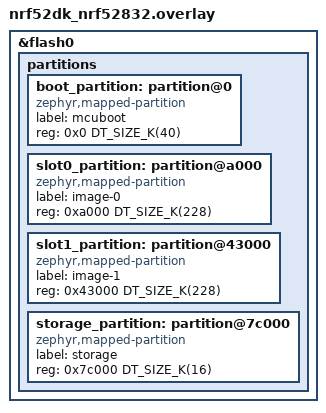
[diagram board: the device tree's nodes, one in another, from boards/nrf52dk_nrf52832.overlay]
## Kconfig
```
#
# Copyright (c) 2018 Nordic Semiconductor
#
# SPDX-License-Identifier: LicenseRef-Nordic-5-Clause
#

# Make the NCS SMP-BLE OTA DFU sample option (CONFIG_NCS_SAMPLE_MCUMGR_BT_OTA_DFU)
# available to this application.
osource "$(ZEPHYR_NRF_MODULE_DIR)/samples/common/mcumgr_bt_ota_dfu/Kconfig"

source "Kconfig.zephyr"

menu "Nordic LED-Button BLE GATT service sample"

config BT_LBS_SECURITY_ENABLED
	bool "Enable security"
	default y
	select BT_SMP
	select BT_SETTINGS
	select FLASH
	select FLASH_PAGE_LAYOUT
	select FLASH_MAP
	select ZMS if (SOC_FLASH_NRF_RRAM || SOC_FLASH_NRF_MRAM)
	select NVS if !(SOC_FLASH_NRF_RRAM || SOC_FLASH_NRF_MRAM)
	select SETTINGS
	help
	  "Enable BLE security for the LED-Button service"

endmenu
```

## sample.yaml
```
sample:
  description: nRF Connect SDK Intermediate Course by Nordic Developer Academy (https://academy.nordicsemi.com/)
  name: nRF Connect SDK Intermediate Course - Lesson 9 Exercise 6 Solution (FOTA over BLE via nRF Cloud)
  
common: 
    sysbuild: true
    build_only: true
    integration_platforms: 
      - nrf52dk/nrf52832
      - nrf52833dk/nrf52833
      - nrf52840dk/nrf52840
      - nrf5340dk/nrf5340/cpuapp
      - nrf5340dk/nrf5340/cpuapp/ns
      - nrf54l15dk/nrf54l15/cpuapp
      - nrf54lc10dk/nrf54lc10a/cpuapp
      - nrf54ls05dk/nrf54ls05b/cpuapp
      - nrf54lm20dk/nrf54lm20a/cpuapp
    platform_allow:
      - nrf52dk/nrf52832
      - nrf52833dk/nrf52833
      - nrf52840dk/nrf52840
      - nrf5340dk/nrf5340/cpuapp
      - nrf5340dk/nrf5340/cpuapp/ns
      - nrf54l15dk/nrf54l15/cpuapp
      - nrf54lc10dk/nrf54lc10a/cpuapp
      - nrf54ls05dk/nrf54ls05b/cpuapp
      - nrf54lm20dk/nrf54lm20a/cpuapp
    
tests:
  ncs_inter.l9.e6_sol: {}
```

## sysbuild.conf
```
SB_CONFIG_BOOTLOADER_MCUBOOT=y
```

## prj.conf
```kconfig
#
# Copyright (c) 2018 Nordic Semiconductor
#
# SPDX-License-Identifier: LicenseRef-Nordic-5-Clause
#
CONFIG_NCS_SAMPLES_DEFAULTS=y

CONFIG_BT=y
CONFIG_BT_PERIPHERAL=y
CONFIG_BT_DEVICE_NAME="Nordic_LBS"

# Enable the LBS service
CONFIG_BT_LBS=y
CONFIG_BT_LBS_POLL_BUTTON=y
CONFIG_DK_LIBRARY=y

CONFIG_SYSTEM_WORKQUEUE_STACK_SIZE=2048

# Carried over from Exercise 5: FOTA over Bluetooth LE (MCUboot is enabled in sysbuild.conf)
CONFIG_NCS_SAMPLE_MCUMGR_BT_OTA_DFU=y
# Show OS/firmware version fields in the nRF Connect Device Manager app
CONFIG_MCUMGR_GRP_OS_INFO=y

# STEP 1.1 - Preserve Bluetooth bonds across a firmware upgrade.
# Because the device stores settings in ZMS/NVS, the OTA DFU sample auto-enables a basic-group
# "storage erase" command that lets the Device Manager app wipe the settings partition (and your
# bonds) during an update. Disable it so the bond survives the upgrade and the phone reconnects
# without re-pairing.
CONFIG_MCUMGR_GRP_ZBASIC_STORAGE_ERASE=n

# STEP 1.2 - Enable the Memfault SDK and set your nRF Cloud (powered by Memfault) project key
CONFIG_MEMFAULT=y
CONFIG_MEMFAULT_NCS_PROJECT_KEY="your-project-key-here"
CONFIG_MEMFAULT_LOG_LEVEL_INF=y
# Software type reported to nRF Cloud. Must match the OTA release's Software Type. nRF Cloud ties
# the nrf54l15dk hardware type to "main", so report "main" (NCS otherwise defaults this to "app").
CONFIG_MEMFAULT_NCS_FW_TYPE="main"

# STEP 1.3 - Enable the Memfault Diagnostic Service (MDS) so the device's data
# (current firmware version, heartbeats, crashes) reaches nRF Cloud over BLE.
# MDS access is gated behind an encrypted connection, so privacy/bonding is required.
CONFIG_BT_MDS=y
CONFIG_BT_PRIVACY=y

# STEP 1.4 - Provide the Memfault device serial automatically from the hardware UID
CONFIG_HW_ID_LIBRARY=y
CONFIG_HW_ID_LIBRARY_SOURCE_DEVICE_ID=y

# STEP 1.5 - Set the firmware version. The two strings must always match.
# The solution shows the second release (0.0.2) delivered over the air; the
# first image flashed to the device in the exercise is 0.0.1.
CONFIG_MEMFAULT_NCS_FW_VERSION_STATIC=y
CONFIG_MEMFAULT_NCS_FW_VERSION="0.0.2"
CONFIG_MCUBOOT_IMGTOOL_SIGN_VERSION="0.0.2"
```

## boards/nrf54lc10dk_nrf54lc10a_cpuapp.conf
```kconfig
CONFIG_CBPRINTF_NANO=y
CONFIG_LOG_MODE_MINIMAL=y
CONFIG_ASSERT=n
CONFIG_BOOT_BANNER=n
```

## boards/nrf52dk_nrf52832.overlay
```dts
/*
 * nRF52833DK flash re-partition (Partition Manager disabled, DTS authoritative).
 *
 * Change vs. the board default: mcuboot (boot_partition) is 8 KB smaller and the
 * application slot (slot0_partition / image-0) is 8 KB bigger. slot0's end address
 * is unchanged, so slot1 and storage keep their original addresses.
 *
 * MCUboot swap-based DFU requires slot0 and slot1 to be equal, so slot1 also grows
 * to 228 KB; the extra 8 KB is reclaimed from storage (24 KB -> 16 KB).
 *
 *   boot_partition    0x00000  40 KB  (was 48 KB)
 *   slot0_partition   0x0a000 228 KB  (was 220 KB)
 *   slot1_partition   0x43000 228 KB  (was 220 KB)
 *   storage_partition 0x7c000  16 KB  (was 24 KB)
 */

/delete-node/ &boot_partition;
/delete-node/ &slot0_partition;
/delete-node/ &slot1_partition;
/delete-node/ &storage_partition;

&flash0 {
	partitions {
		boot_partition: partition@0 {
			compatible = "zephyr,mapped-partition";
			label = "mcuboot";
			reg = <0x0 DT_SIZE_K(40)>;
		};

		slot0_partition: partition@a000 {
			compatible = "zephyr,mapped-partition";
			label = "image-0";
			reg = <0xa000 DT_SIZE_K(228)>;
		};

		slot1_partition: partition@43000 {
			compatible = "zephyr,mapped-partition";
			label = "image-1";
			reg = <0x43000 DT_SIZE_K(228)>;
		};

		storage_partition: partition@7c000 {
			compatible = "zephyr,mapped-partition";
			label = "storage";
			reg = <0x7c000 DT_SIZE_K(16)>;
		};
	};
};
```

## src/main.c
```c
/*
 * Copyright (c) 2018 Nordic Semiconductor ASA
 *
 * SPDX-License-Identifier: LicenseRef-Nordic-5-Clause
 */

#include <zephyr/types.h>
#include <stddef.h>
#include <string.h>
#include <errno.h>
#include <zephyr/sys/printk.h>
#include <zephyr/sys/byteorder.h>
#include <zephyr/kernel.h>
#include <zephyr/drivers/gpio.h>
#include <soc.h>

#include <zephyr/bluetooth/bluetooth.h>
#include <zephyr/bluetooth/hci.h>
#include <zephyr/bluetooth/conn.h>
#include <zephyr/bluetooth/uuid.h>
#include <zephyr/bluetooth/gatt.h>

#include <bluetooth/services/lbs.h>

/* STEP 2.1 - Include the Memfault Diagnostic Service header */
#include <bluetooth/services/mds.h>

#include <zephyr/settings/settings.h>

#include <dk_buttons_and_leds.h>

#define DEVICE_NAME             CONFIG_BT_DEVICE_NAME
#define DEVICE_NAME_LEN         (sizeof(DEVICE_NAME) - 1)


#define RUN_STATUS_LED          DK_LED1
#define CON_STATUS_LED          DK_LED2
#define RUN_LED_BLINK_INTERVAL  1000

#define USER_LED                DK_LED3

#define USER_BUTTON             DK_BTN1_MSK

static bool app_button_state;
static struct k_work adv_work;

#if defined(CONFIG_BT_MDS)
/* STEP 2.2 - Track the connection that is allowed to access MDS */
static struct bt_conn *mds_conn;
#endif

static const struct bt_data ad[] = {
	BT_DATA_BYTES(BT_DATA_FLAGS, (BT_LE_AD_GENERAL | BT_LE_AD_NO_BREDR)),
	BT_DATA(BT_DATA_NAME_COMPLETE, DEVICE_NAME, DEVICE_NAME_LEN),
};

static const struct bt_data sd[] = {
	BT_DATA_BYTES(BT_DATA_UUID128_ALL, BT_UUID_LBS_VAL),
};

static void adv_work_handler(struct k_work *work)
{
	int err = bt_le_adv_start(BT_LE_ADV_CONN_FAST_2, ad, ARRAY_SIZE(ad), sd, ARRAY_SIZE(sd));

	if (err) {
		printk("Advertising failed to start (err %d)\n", err);
		return;
	}

	printk("Advertising successfully started\n");
}

static void advertising_start(void)
{
	k_work_submit(&adv_work);
}

static void connected(struct bt_conn *conn, uint8_t err)
{
	if (err) {
		printk("Connection failed, err 0x%02x %s\n", err, bt_hci_err_to_str(err));
		return;
	}

	printk("Connected\n");

	dk_set_led_on(CON_STATUS_LED);

#if defined(CONFIG_BT_MDS)
	/* STEP 2.3 - Request an encrypted link. MDS data may only be accessed
	 * over an encrypted (and, here, bonded) connection.
	 */
	bt_conn_set_security(conn, BT_SECURITY_L2);
#endif
}

static void disconnected(struct bt_conn *conn, uint8_t reason)
{
	printk("Disconnected, reason 0x%02x %s\n", reason, bt_hci_err_to_str(reason));

	dk_set_led_off(CON_STATUS_LED);
/* STEP 2.3 (cont.) - Clear mds_conn here if it matches the closing connection */
#if defined(CONFIG_BT_MDS)
	if (conn == mds_conn) {
		mds_conn = NULL;
	}
#endif
}

static void recycled_cb(void)
{
	printk("Connection object available from previous conn. Disconnect is complete!\n");
	advertising_start();
}

#ifdef CONFIG_BT_LBS_SECURITY_ENABLED
static void security_changed(struct bt_conn *conn, bt_security_t level,
			     enum bt_security_err err)
{
	char addr[BT_ADDR_LE_STR_LEN];

	bt_addr_le_to_str(bt_conn_get_dst(conn), addr, sizeof(addr));

	if (!err) {
		printk("Security changed: %s level %u\n", addr, level);
	} else {
		printk("Security failed: %s level %u err %d %s\n", addr, level, err,
		       bt_security_err_to_str(err));
	}

#if defined(CONFIG_BT_MDS)
	/* STEP 2.4 - Once the link is encrypted, allow this connection to access MDS */
	if (!err && level >= BT_SECURITY_L2 && !mds_conn) {
		mds_conn = conn;
	}
#endif
}
#endif

BT_CONN_CB_DEFINE(conn_callbacks) = {
	.connected        = connected,
	.disconnected     = disconnected,
	.recycled         = recycled_cb,
#ifdef CONFIG_BT_LBS_SECURITY_ENABLED
	.security_changed = security_changed,
#endif
};

#if defined(CONFIG_BT_LBS_SECURITY_ENABLED)
/* No passkey display/entry callbacks -> pairing uses "Just Works" (no PIN),
 * which still yields an encrypted link (BT_SECURITY_L2) for MDS access.
 */
static void auth_cancel(struct bt_conn *conn)
{
	char addr[BT_ADDR_LE_STR_LEN];

	bt_addr_le_to_str(bt_conn_get_dst(conn), addr, sizeof(addr));

	printk("Pairing cancelled: %s\n", addr);
}

static void pairing_complete(struct bt_conn *conn, bool bonded)
{
	char addr[BT_ADDR_LE_STR_LEN];

	bt_addr_le_to_str(bt_conn_get_dst(conn), addr, sizeof(addr));

	printk("Pairing completed: %s, bonded: %d\n", addr, bonded);
}

static void pairing_failed(struct bt_conn *conn, enum bt_security_err reason)
{
	char addr[BT_ADDR_LE_STR_LEN];

	bt_addr_le_to_str(bt_conn_get_dst(conn), addr, sizeof(addr));

	printk("Pairing failed conn: %s, reason %d %s\n", addr, reason,
	       bt_security_err_to_str(reason));
}

static struct bt_conn_auth_cb conn_auth_callbacks = {
	.cancel = auth_cancel,
};

static struct bt_conn_auth_info_cb conn_auth_info_callbacks = {
	.pairing_complete = pairing_complete,
	.pairing_failed = pairing_failed
};
#else
static struct bt_conn_auth_cb conn_auth_callbacks;
static struct bt_conn_auth_info_cb conn_auth_info_callbacks;
#endif

#if defined(CONFIG_BT_MDS)
/* STEP 2.5 - Only allow the paired/encrypted connection to access MDS */
static bool mds_access_enable(struct bt_conn *conn)
{
	if (mds_conn && (conn == mds_conn)) {
		return true;
	}

	return false;
}

static const struct bt_mds_cb mds_cb = {
	.access_enable = mds_access_enable,
};
#endif /* CONFIG_BT_MDS */

static void app_led_cb(bool led_state)
{
	dk_set_led(USER_LED, led_state);
}

static bool app_button_cb(void)
{
	return app_button_state;
}

static struct bt_lbs_cb lbs_callbacs = {
	.led_cb    = app_led_cb,
	.button_cb = app_button_cb,
};

static void button_changed(uint32_t button_state, uint32_t has_changed)
{
	if (has_changed & USER_BUTTON) {
		uint32_t user_button_state = button_state & USER_BUTTON;

		bt_lbs_send_button_state(user_button_state);
		app_button_state = user_button_state ? true : false;
	}
}

static int init_button(void)
{
	int err;

	err = dk_buttons_init(button_changed);
	if (err) {
		printk("Cannot init buttons (err: %d)\n", err);
	}

	return err;
}

int main(void)
{
	int blink_status = 0;
	int err;

	printk("Starting Bluetooth Peripheral LBS sample\n");

	err = dk_leds_init();
	if (err) {
		printk("LEDs init failed (err %d)\n", err);
		return 0;
	}

	err = init_button();
	if (err) {
		printk("Button init failed (err %d)\n", err);
		return 0;
	}

#if defined(CONFIG_BT_MDS)
	/* STEP 2.6 - Register the MDS access callback before enabling Bluetooth */
	err = bt_mds_cb_register(&mds_cb);
	if (err) {
		printk("Memfault Diagnostic service callback registration failed (err %d)\n", err);
		return 0;
	}
#endif

	if (IS_ENABLED(CONFIG_BT_LBS_SECURITY_ENABLED)) {
		err = bt_conn_auth_cb_register(&conn_auth_callbacks);
		if (err) {
			printk("Failed to register authorization callbacks.\n");
			return 0;
		}

		err = bt_conn_auth_info_cb_register(&conn_auth_info_callbacks);
		if (err) {
			printk("Failed to register authorization info callbacks.\n");
			return 0;
		}
	}

	err = bt_enable(NULL);
	if (err) {
		printk("Bluetooth init failed (err %d)\n", err);
		return 0;
	}

	printk("Bluetooth initialized\n");

	if (IS_ENABLED(CONFIG_SETTINGS)) {
		settings_load();
	}

	err = bt_lbs_init(&lbs_callbacs);
	if (err) {
		printk("Failed to init LBS (err:%d)\n", err);
		return 0;
	}

	k_work_init(&adv_work, adv_work_handler);
	advertising_start();

	for (;;) {
		dk_set_led(RUN_STATUS_LED, (++blink_status) % 2);
		k_sleep(K_MSEC(RUN_LED_BLINK_INTERVAL));
	}
}
```

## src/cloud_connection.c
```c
/* Copyright (c) 2023 Nordic Semiconductor ASA
 *
 * SPDX-License-Identifier: LicenseRef-Nordic-5-Clause
 */

#include <zephyr/kernel.h>
#include <zephyr/net/socket.h>
#include <zephyr/net/conn_mgr_connectivity.h>
#include <zephyr/logging/log.h>
#include <stdio.h>
#include <date_time.h>
#include <net/nrf_cloud.h>
#include <net/nrf_cloud_codec.h>
#include <net/nrf_cloud_log.h>
#include "app_version.h"

/* STEP 6.1.1 - Dependency for sys_reboot() */
#include <zephyr/sys/reboot.h>

#include "cloud_connection.h"

LOG_MODULE_REGISTER(cloud_connection, 4);

/* Internal state */

/* Pendable events that threads can wait for. */
#define NETWORK_READY			BIT(0)
#define CLOUD_CONNECTED			BIT(1)
#define CLOUD_READY			BIT(2)
#define CLOUD_DISCONNECTED		BIT(3)
#define DATE_TIME_KNOWN			BIT(4)
static K_EVENT_DEFINE(cloud_events);

/* Atomic status flag tracking whether an initial association is in progress. */
atomic_t initial_association;

/* Helper functions for pending on pendable events. */
bool await_network_ready(k_timeout_t timeout)
{
	return k_event_wait(&cloud_events, NETWORK_READY, false, timeout) != 0;
}

bool await_cloud_ready(k_timeout_t timeout)
{
	return k_event_wait(&cloud_events, CLOUD_READY, false, timeout) != 0;
}

bool await_cloud_disconnected(k_timeout_t timeout)
{
	return k_event_wait(&cloud_events, CLOUD_DISCONNECTED, false, timeout) != 0;
}

bool await_date_time_known(k_timeout_t timeout)
{
	return k_event_wait(&cloud_events, DATE_TIME_KNOWN, false, timeout) != 0;
}

/* Wait for a connection result, and return true if connection was successful within the timeout,
 * otherwise return false.
 */
static bool await_connection_result(k_timeout_t timeout)
{
	/* After a connection attempt, either CLOUD_CONNECTED or CLOUD_DISCONNECTED will be
	 * raised, depending on whether the connection succeeded.
	 */
	uint32_t events = CLOUD_CONNECTED | CLOUD_DISCONNECTED;

	return (k_event_wait(&cloud_events, events, false, timeout) & CLOUD_CONNECTED) != 0;
}

/* Delayable work item for handling cloud readiness timeout.
 * The work item is scheduled at a delay any time connection starts and is cancelled when the
 * connection to nRF Cloud becomes ready to use (signalled by NRF_CLOUD_EVT_READY).
 *
 * If the work item executes, that means the nRF Cloud connection did not become ready for use
 * within the delay, and thus the connection should be reset (and then try again later).
 */
static void ready_timeout_work_fn(struct k_work *work)
{
	ARG_UNUSED(work);
	LOG_INF("nRF Cloud connection did not become ready in time, disconnecting and retrying...");
	disconnect_cloud();
}

static K_WORK_DELAYABLE_DEFINE(ready_timeout_work, ready_timeout_work_fn);


/* Start the readiness timeout if readiness is not already achieved. */
static void start_readiness_timeout(void)
{
	/* It doesn't make sense to start the readiness timeout if we're already ready. */
	if (!k_event_test(&cloud_events, CLOUD_READY)) {
		return;
	}

	LOG_DBG("Starting cloud connection readiness timeout for %d seconds",600);
	k_work_reschedule(&ready_timeout_work, K_SECONDS(600));
}

static void clear_readiness_timeout(void)
{
	LOG_DBG("Stopping cloud connection readiness timeout");
	k_work_cancel_delayable(&ready_timeout_work);
}

/**
 * @brief Update internal state in response to achieving connection.
 */
static void cloud_connected(void)
{
	LOG_INF("Connected to nRF Cloud");

	/* Notify that the nRF Cloud connection is established. */
	k_event_post(&cloud_events, CLOUD_CONNECTED);
}

/**
 * @brief Update internal state in response to achieving readiness.
 */
static void cloud_ready(void)
{
	/* Clear the readiness timeout, since we have become ready. */
	clear_readiness_timeout();

	/* Notify that the nRF Cloud connection is ready for use. */
	k_event_post(&cloud_events, CLOUD_READY);
}

/* A callback that the application may register in order to handle custom device messages.
 * This is really a convenience callback to help keep this sample clean and modular. You could
 * implement device message handling directly in the cloud_event_handler if desired.
 */
static dev_msg_handler_cb_t general_dev_msg_handler;
void register_general_dev_msg_handler(dev_msg_handler_cb_t handler_cb)
{
	general_dev_msg_handler = handler_cb;
}

/* This function causes the cloud to disconnect, and updates internal state accordingly.
 *
 * It is also triggerd by cloud disconnection, to update internal state.
 *
 * In this latter case, an unnecessary "Disconnecting from nRF Cloud" and
 * "Already disconnected from nRF Cloud" will be printed.
 *
 * This is done to keep the sample simple, though the log messages may be a bit confusing.
 */
void disconnect_cloud(void)
{
	/* Clear the readiness timeout in case it was running. */
	clear_readiness_timeout();

	/* Clear the Ready and Connected events, no longer accurate. */
	k_event_clear(&cloud_events, CLOUD_READY | CLOUD_CONNECTED);

	/* Clear the initial association flag, no longer accurate. */
	atomic_set(&initial_association, false);

	/* Disconnect from nRF Cloud -- Blocking call
	 * Will no-op and return -EACCES if already disconnected.
	 */
	LOG_INF("Disconnecting from nRF Cloud");
	int err;

	err = nrf_cloud_disconnect();
	/* nrf_cloud_disconnect returns -EACCES if we are not currently in a connected state.
	 * nrf_cloud_coap_disconnect returns -ENOTCONN if socket is not open.
	 */
	if ((err == -EACCES) || (err == -ENOTCONN)) {
		LOG_DBG("Already disconnected from nRF Cloud");
	} else if (err) {
		LOG_ERR("Cannot disconnect from nRF Cloud, error: %d. Continuing anyways", err);
	} else {
		LOG_INF("Successfully disconnected from nRF Cloud");
	}

	/* Fire the disconnected event. */
	k_event_post(&cloud_events, CLOUD_DISCONNECTED);
}

/**
 * @brief Attempt to connect to nRF Cloud and update internal state accordingly.
 *
 * Blocks until connection attempt either succeeds or fails.
 *
 * @retval true if successful
 * @retval false if connection failed
 */
static bool connect_cloud(void)
{
	char device_id[NRF_CLOUD_CLIENT_ID_MAX_LEN + 1];
	int err;

	LOG_INF("Connecting to nRF Cloud");

	err = nrf_cloud_client_id_get(device_id, sizeof(device_id));
	if (!err) {
		LOG_INF("Device ID: %s", device_id);
	} else {
		LOG_ERR("Error requesting the device id: %d", err);
	}

	/* Clear the disconnected flag, no longer accurate. */
	k_event_clear(&cloud_events, CLOUD_DISCONNECTED);

	/* Connect to nRF Cloud -- Non-blocking. State updates are handled in callbacks. */
	err = nrf_cloud_connect();

	/* If we were already connected, treat as a successful connection, but do nothing. */
	if (err == NRF_CLOUD_CONNECT_RES_ERR_ALREADY_CONNECTED) {
		LOG_WRN("Already connected to nRF Cloud");
		return true;
	}

	/* If the connection attempt fails immediately, report and exit. */
	if (err != 0) {
		LOG_ERR("Could not connect to nRF Cloud, error: %d", err);
		return false;
	}

	/* Wait for the connection to either complete or fail. */
	if (!await_connection_result(K_FOREVER)) {
		LOG_ERR("Could not connect to nRF Cloud");
		return false;
	}

	/* If connection succeeded and we aren't already ready, start the readiness timeout.
	 * (Readiness check is performed by start_readiness_timeout).
	 */
	start_readiness_timeout();
	return true;
}

/* External event handlers */

/* Handler for L4/connectivity events
 * This allows the cloud module to react to network gain and loss.
 * The conn_mgr subsystem is responsible for seeking / maintaining network connectivity and
 * firing these events.
 */
static struct net_mgmt_event_callback l4_callback;
static void l4_event_handler(struct net_mgmt_event_callback *cb,
			     uint64_t event, struct net_if *iface)
{
	if (event == NET_EVENT_L4_CONNECTED) {
		LOG_INF("Network connectivity gained!");

		k_sleep(K_MSEC(1000));

		/* Set the network ready flag */
		k_event_post(&cloud_events, NETWORK_READY);

		/* If LTE-event-driven date_time updates are disabled, manually trigger a date_time
		 * timestamp refresh.
		 *
		 * Note: The CONFIG_DATE_TIME_AUTO_UPDATE setting controls specifically whether
		 * LTE-event-driven date_time updates are enabled. The date_time library will still
		 * periodically refresh its timestamp if CONFIG_DATE_TIME_AUTO_UPDATE is disabled,
		 * but this refresh is infrequent, so we are manually requesting a refresh
		 * whenever internet access becomes available so that we get a timestamp
		 * immediately.
		 */

	} else if (event == NET_EVENT_L4_DISCONNECTED) {
		LOG_INF("Network connectivity lost!");

		/* Clear the network ready flag */
		k_event_clear(&cloud_events, NETWORK_READY);

		/* Disconnect from cloud as well. */
		disconnect_cloud();
	}
}

/* Handler for date_time library events, used to keep track of whether the current time is known */
static void date_time_event_handler(const struct date_time_evt *date_time_evt)
{
	if (date_time_is_valid()) {
		k_event_post(&cloud_events, DATE_TIME_KNOWN);
	} else {
		k_event_clear(&cloud_events, DATE_TIME_KNOWN);
	}
}

#if defined(CONFIG_NRF_CLOUD_MQTT)
/* Handler for nRF Cloud shadow events */
static void handle_shadow_event(struct nrf_cloud_obj_shadow_data *const shadow)
{
	if (!shadow) {
		return;
	}

	int err;

	if (shadow->type == NRF_CLOUD_OBJ_SHADOW_TYPE_DELTA) {
		LOG_DBG("Shadow: Delta - version: %d, timestamp: %lld",
			shadow->delta->ver,
			shadow->delta->ts);

		/* Always accept since this sample, by default,
		 * doesn't have any application specific shadow handling
		 */
		err = nrf_cloud_obj_shadow_delta_response_encode(&shadow->delta->state, true);
		if (err) {
			LOG_ERR("Failed to encode shadow response: %d", err);
			return;
		}

		err = nrf_cloud_obj_shadow_update(&shadow->delta->state);
		if (err) {
			LOG_ERR("Failed to send shadow response, error: %d", err);
		}
	} else if ((shadow->type == NRF_CLOUD_OBJ_SHADOW_TYPE_TF) && shadow->transform)
	{
		if (shadow->transform->is_err) {
			LOG_ERR("Shadow transform error received");
			return;
		}
		LOG_DBG("Shadow transform result received");
	}
}

/* Handler for events from nRF Cloud Lib. */
static void cloud_event_handler(const struct nrf_cloud_evt *nrf_cloud_evt)
{
	switch (nrf_cloud_evt->type) {
	case NRF_CLOUD_EVT_TRANSPORT_CONNECTED:
		LOG_DBG("NRF_CLOUD_EVT_TRANSPORT_CONNECTED");

		/* Handle connection success. */
		cloud_connected();
		break;
	case NRF_CLOUD_EVT_TRANSPORT_CONNECTING:
		LOG_DBG("NRF_CLOUD_EVT_TRANSPORT_CONNECTING");
		break;
	case NRF_CLOUD_EVT_TRANSPORT_CONNECT_ERROR:
		LOG_DBG("NRF_CLOUD_EVT_TRANSPORT_CONNECT_ERROR: %d", nrf_cloud_evt->status);

		/* Disconnect from cloud immediately rather than wait for retry timeout. */
		disconnect_cloud();

		break;
	case NRF_CLOUD_EVT_USER_ASSOCIATION_REQUEST:
		LOG_DBG("NRF_CLOUD_EVT_USER_ASSOCIATION_REQUEST");
		/* This event indicates that the user must associate the device with their
		 * nRF Cloud account in the nRF Cloud portal.
		 *
		 * The device must then disconnect and reconnect to nRF Cloud after association
		 * succeeds.
		 */
		LOG_INF("Please add this device to your cloud account in the nRF Cloud portal.");

		/* Store the fact that this is an initial association.
		 *
		 * This will cause the next NRF_CLOUD_EVT_USER_ASSOCIATED event to
		 * disconnect and reconnect the device to nRF Cloud, which is required
		 * when devices are first associated with an nRF Cloud account.
		 */
		atomic_set(&initial_association, true);
		break;
	case NRF_CLOUD_EVT_USER_ASSOCIATED:
		LOG_DBG("NRF_CLOUD_EVT_USER_ASSOCIATED");
		/* Indicates successful association with an nRF Cloud account.
		 * Fired every time the device connects (unless the device is not associated).
		 *
		 * If this is an initial association, the device must disconnect and
		 * and reconnect before using nRF Cloud.
		 */

		if (atomic_get(&initial_association)) {
			/* Disconnect as is required.
			 * The connection loop will handle reconnection afterwards.
			 */
			LOG_INF("Device successfully associated with cloud! Reconnecting");
			disconnect_cloud();
		}
		break;
	case NRF_CLOUD_EVT_READY:
		LOG_DBG("NRF_CLOUD_EVT_READY");

		/* Handle achievement of readiness */
		cloud_ready();

		/* The nRF Cloud library will automatically update the
		 * device's shadow based on the build configuration.
		 * See config NRF_CLOUD_SEND_SHADOW_INFO for details.
		 */

		break;
	case NRF_CLOUD_EVT_SENSOR_DATA_ACK:
		LOG_DBG("NRF_CLOUD_EVT_SENSOR_DATA_ACK");
		break;
	case NRF_CLOUD_EVT_TRANSPORT_DISCONNECTED:
		LOG_DBG("NRF_CLOUD_EVT_TRANSPORT_DISCONNECTED");

		/* The nRF Cloud library itself has disconnected for some reason.
		 * Execute a manual disconnect so that the event flags are updated.
		 * The internal nrf_cloud_disconnect call will no-op.
		 */
		disconnect_cloud();

		break;
	case NRF_CLOUD_EVT_ERROR:
		LOG_DBG("NRF_CLOUD_EVT_ERROR: %d", nrf_cloud_evt->status);
		break;
	case NRF_CLOUD_EVT_RX_DATA_GENERAL:
		LOG_DBG("NRF_CLOUD_EVT_RX_DATA_GENERAL");
		LOG_DBG("%d bytes received from cloud", nrf_cloud_evt->data.len);

		/* Pass the device message along to the application, if it is listening */
		if (general_dev_msg_handler) {
			/* To keep the sample simple, we invoke the callback directly.
			 * If you want to do complex operations in this callback without blocking
			 * receipt of data from nRF Cloud, you should set up a work queue and pass
			 * messages to it either here, or from inside the callback.
			 */
			general_dev_msg_handler(&nrf_cloud_evt->data);
		}

		break;
	case NRF_CLOUD_EVT_RX_DATA_SHADOW: {
		LOG_DBG("NRF_CLOUD_EVT_RX_DATA_SHADOW");
		handle_shadow_event(nrf_cloud_evt->shadow);
		break;
	}
	case NRF_CLOUD_EVT_FOTA_START:
		LOG_DBG("NRF_CLOUD_EVT_FOTA_START");
		break;
	case NRF_CLOUD_EVT_FOTA_DONE: {
		enum nrf_cloud_fota_type fota_type = NRF_CLOUD_FOTA_TYPE__INVALID;

		if (nrf_cloud_evt->data.ptr) {
			fota_type = *((enum nrf_cloud_fota_type *) nrf_cloud_evt->data.ptr);
		}

		LOG_DBG("NRF_CLOUD_EVT_FOTA_DONE, FOTA type: %s",
			fota_type == NRF_CLOUD_FOTA_APPLICATION	  ?		"Application"	:
			fota_type == NRF_CLOUD_FOTA_MODEM_DELTA	  ?		"Modem (delta)"	:
			fota_type == NRF_CLOUD_FOTA_MODEM_FULL	  ?		"Modem (full)"	:
			fota_type == NRF_CLOUD_FOTA_BOOTLOADER	  ?		"Bootloader"	:
										"Invalid");

    /* STEP 6.1.2 - Reboot since the FOTA is done. */
    /* Note: The Multi Service Sample has a reboot command here, which was removed for this DevAcademy exercise. */
	  sys_reboot(SYS_REBOOT_COLD);
		break;
	}
	case NRF_CLOUD_EVT_FOTA_ERROR:
		LOG_DBG("NRF_CLOUD_EVT_FOTA_ERROR");
		break;
	default:
		LOG_DBG("Unknown event type: %d", nrf_cloud_evt->type);
		break;
	}
}
#endif /* CONFIG_NRF_CLOUD_MQTT */

/**
 * @brief Set up for the nRF Cloud connection (without connecting)
 *
 * Sets up required event hooks and initializes the nrf_cloud library.
 *
 * @return int - 0 on success, otherwise negative error code.
 */
static int setup_cloud(void)
{
	int err;

	/* Register to be notified of network availability changes.
	 *
	 * If the chosen connectivity layer becomes ready instantaneously, it is possible that
	 * L4_CONNECTED will be fired before reaching this function, in which case we will miss
	 * the notification.
	 *
	 * If that is a serious concern, use SYS_INIT with priority 0 (less than
	 * CONFIG_NET_CONNECTION_MANAGER_PRIORITY) to register this hook before conn_mgr
	 * initializes.
	 *
	 * In reality, connectivity layers such as LTE take some time to go online, so registering
	 * the hook here is fine.
	 */
	net_mgmt_init_event_callback(
		&l4_callback, l4_event_handler, NET_EVENT_L4_CONNECTED | NET_EVENT_L4_DISCONNECTED
	);
	net_mgmt_add_event_callback(&l4_callback);

	/* Register to be notified when the modem has figured out the current time. */
	date_time_register_handler(date_time_event_handler);

	/* Initialize nrf_cloud library. */
	struct nrf_cloud_init_param params = {
		.event_handler = cloud_event_handler,
		.application_version = APP_VERSION_STRING
	};

	err = nrf_cloud_init(&params);
	if (err) {
		LOG_ERR("nRF Cloud library could not be initialized, error: %d", err);
		return err;
	}


	return 0;
}

/* Check whether nRF Cloud credentials are installed. If not, sleep forever. */
static void check_credentials(void)
{
	int status = nrf_cloud_credentials_configured_check();

	if (status == -ENOTSUP) {
		k_sleep(K_FOREVER);
	} else if (status) {
		LOG_ERR("Error while checking for credentials: %d. Proceeding anyway.", status);
	}
}

void cloud_connection_thread_fn(void)
{

	LOG_INF("Enabling connectivity...");
	conn_mgr_all_if_connect(true);

	LOG_INF("Setting up nRF Cloud library...");
	if (setup_cloud()) {
		LOG_ERR("Fatal: nRF Cloud library setup failed");
		return;
	}

	/* Check for credentials, if the feature is enabled. */
	if (IS_ENABLED(CONFIG_NRF_CLOUD_CHECK_CREDENTIALS)) {
		check_credentials();
	}

	/* Indefinitely maintain a connection to nRF Cloud whenever the network is reachable. */
	while (true) {
		LOG_INF("Waiting for network ready...");

		(void)await_network_ready(K_FOREVER);

		LOG_INF("Network is ready");


		/* Attempt to connect to nRF Cloud. */
		if (connect_cloud()) {
			LOG_DBG("Awaiting disconnection from nRF Cloud");

			/* and then wait patiently for a connection problem. */
			(void)await_cloud_disconnected(K_FOREVER);

			LOG_INF("Disconnected from nRF Cloud");
		}

		LOG_INF("Retrying in %d seconds...", 60);

		/* Wait a bit before trying again. */
		k_sleep(K_SECONDS(60));
	}
}
```
